# dma: IP-XACT component
VLNV spiritconsortium.org:Leon2RTL:dma:1.2

## Bus interfaces (logical=physical port)
AHBClk: target spiritconsortium.org:busdef.clock:clock:1.0
  CLK=clk
AHBReset: target spiritconsortium.org:busdef.reset:reset:1.0
  RESETn=rst
ambaAHB: initiator amba.com:AMBA2:AHB:r2p0_6, address space main
  HRDATA=hrdata, HGRANTx=hgrant, HADDR=haddr, HTRANS=htrans, HWRITE=hwrite, HSIZE=hsize, HBURST=hburst, HPROT=hprot, HWDATA=hwdata, HBUSREQx=hbusreq, HLOCKx=hlock, HREADY=hready, HRESP=hresp, HCLK=clk, HRESETn=rst
ambaAPB: target amba.com:AMBA2:APB:r2p0_4, memory map ambaAPB
  PADDR=paddr, PWDATA=pwdata, PRDATA=prdata, PWRITE=pwrite, PSELx=psel, PENABLE=penable, PCLK=clk, PRESETn=rst
interrupt: initiator spiritconsortium.org:busdef.interrupt:interrupt:1.0
  IRQ=dirq

## Ports
in clk
in rst
in hready
in hrdata[31:0]
in hresp[1:0]
in hgrant
out haddr[31:0]
out htrans[1:0]
out hwrite
out hsize[2:0]
out hburst[2:0]
out hprot[3:0]
out hwdata[31:0]
out hbusreq
out hlock
in psel
in penable
in paddr[31:0]
in pwrite
in pwdata[31:0]
out prdata[31:0]
out dirq

## Address spaces and blocks
main: range 4 * (2 ** 30), width 32
ambaAPB.defaultid4490081: base 0, range 16, width width

## Registers
Registers are 32-bit, read-write, no defined reset value unless marked. A register's access mark holds for its fields unless they carry their own. Offsets are from the block's base; lines under a group give offsets from that group; [hi:lo] are bit positions; {n}, {i} and the like mark numbered series; 'fields as' and 'values as' point back to an identical list; <NAME> marks a mode.

## ambaAPB.defaultid4490081
Base 0x00000000
0x00 sourceAddress
0x04 destinationAddress
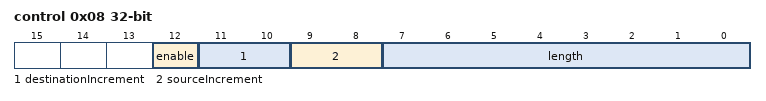
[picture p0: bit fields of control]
0x08 control
  [12] enable wo — Enable transfer
  [11:10] destinationIncrement — 00=no incrment, 01=Byte, 01=half word, 11=Word incrementing of address
  [9:8] sourceIncrement — 00=no incrment, 01=Byte, 01=half word, 11=Word incrementing of address
  [7:0] length — Size of data transfer

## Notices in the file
Copyright (c) 2006, 2008, 2009 The SPIRIT Consortium.
This work forms part of a deliverable of The SPIRIT Consortium.
Use of these materials are governed by the legal terms and conditions
outlined in the disclaimer available from www.spiritconsortium.org.
This source file is provided on an AS IS basis.  The SPIRIT
Consortium disclaims any warranty express or implied including
any warranty of merchantability and fitness for use for a
particular purpose.
The user of the source file shall indemnify and hold The SPIRIT
Consortium and its members harmless from any damages or liability.
